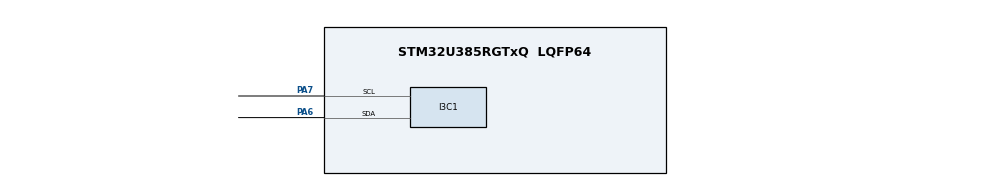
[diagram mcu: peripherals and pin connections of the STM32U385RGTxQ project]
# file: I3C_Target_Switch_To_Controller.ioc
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CORTEX_M33_NS.userName=CORTEX_M33
I3C1.CtrlCapability=ENABLE
I3C1.CtrlRoleRequest=ENABLE
I3C1.IBIPayloadSize=HAL_I3C_PAYLOAD_EMPTY
I3C1.Identifier=0xC6
I3C1.MIPIIdentifier=DEVICE_ID
I3C1.MaxReadDataSize=0xFF
I3C1.MaxWriteDataSize=0xFF
I3C1.Register1=0x0000005e
I3C1.hexBusAvailableDuration=0x5e
Mcu.Family=STM32U3
Mcu.Name=STM32U385RGTxQ
Mcu.Package=LQFP64
Mcu.UserConstants=DEVICE_ID,0x01
NVIC.I3C1_ER_IRQn=true\:0\:0\:false\:false\:true\:true\:true\:true
NVIC.I3C1_EV_IRQn=true\:0\:0\:false\:false\:true\:true\:true\:true
NVIC.PriorityGroup=NVIC_PRIORITYGROUP_4
PA6.Mode=Target
PA6.Signal=I3C1_SDA
PA7.Mode=Target
PA7.Signal=I3C1_SCL
ProjectManager.HeapSize=0x200
ProjectManager.StackSize=0x400
ProjectManager.TargetToolchain=EWARM V9.20
RCC.ADCFreq_Value=96000000
RCC.AHBFreq_Value=96000000
RCC.APB1Freq_Value=96000000
RCC.APB1TimFreq_Value=96000000
RCC.APB2Freq_Value=96000000
RCC.APB2TimFreq_Value=96000000
RCC.APB3Freq_Value=96000000
RCC.CortexFreq_Value=12000000
RCC.HCLKFreq_Value=96000000
RCC.HSE_VALUE=16000000
RCC.HSI48_VALUE=48000000
RCC.HSI_VALUE=16000000
RCC.LSE_VALUE=32768
RCC.LSIDIV_VALUE=32000
RCC.MSISDIV=RCC_MSI_DIV1
RCC.SYSCLKFreq_VALUE=96000000
RCC.USBFreq_Value=96000000
VP_ICACHE_VS_ICACHE.Mode=DirectMappedCache
VP_PWR_VS_DBSignals.Mode=DisableDeadBatterySignals
VP_PWR_VS_LPOM.Mode=PowerOptimisation
VP_PWR_VS_SECSignals.Mode=Security/Privilege
board=custom

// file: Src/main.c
/* USER CODE BEGIN Header */
/**
  ******************************************************************************
  * @file    I3C/I3C_Target_Switch_To_Controller/Src/main.c
  * @author  MCD Application Team
  * @brief   This sample code shows how to use STM32U3xx I3C HAL API to
  *          launch a Controller Roler procedure to a Controller with a communication
  *          process based on Interrupt transfer.
  ******************************************************************************
  * @attention
  *
  * Copyright (c) 2024 STMicroelectronics.
  * All rights reserved.
  *
  * This software is licensed under terms that can be found in the LICENSE file
  * in the root directory of this software component.
  * If no LICENSE file comes with this software, it is provided AS-IS.
  *
  ******************************************************************************
  */
/* USER CODE END Header */
#include "main.h"

/* USER CODE BEGIN PD */
#define I3C_SECONDARY_CONTROLLER_FREQUENCY    2000000  /* I3C Push-Pull Bus frequency: 2 MHz,
                                                          Open Drain is auto-calculated */
/* USER CODE END PD */

I3C_HandleTypeDef hi3c1;

/* USER CODE BEGIN PV */
/* Context buffer related to Frame context, contain different buffer value for a communication */
I3C_XferTypeDef aContextBuffers[2];

/* Variable to catch Controller Role Request event completion */
__IO uint32_t uwCRCompleted = 0;

/* Buffer used for reception during Get CCC procedure */
uint8_t aRxBuffer[0x1F];

/* Buffer used by HAL to compute control data for the Direct Communication */
uint32_t aControlBuffer[0xFF];

/* Descriptor for direct read CCC */
I3C_CCCTypeDef aGET_CCCList[] =
{
    /*   Target Addr              CCC Value    CCC data + defbyte pointer  CCC size + defbyte         Direction       */
    {0x40,          Direct_GETMRL,        {NULL,                  1},              LL_I3C_DIRECTION_READ},
};
/* USER CODE END PV */

void SystemClock_Config(void);
static void MX_GPIO_Init(void);
static void MX_I3C1_Init(void);
static void MX_ICACHE_Init(void);

int main(void)
{

  /* USER CODE BEGIN 1 */
  /* STM32U3xx HAL library initialization:
       - Configure the Flash prefetch
       - Configure the Systick to generate an interrupt each 1 msec
       - Set NVIC Group Priority to 3
       - Low Level Initialization
     */
  /* USER CODE END 1 */

  /* MCU Configuration--------------------------------------------------------*/

  /* Reset of all peripherals, Initializes the Flash interface and the Systick. */
  HAL_Init();

  /* Configure the system clock */
  SystemClock_Config();

  /* Initialize all configured peripherals */
  MX_GPIO_Init();
  MX_I3C1_Init();
  MX_ICACHE_Init();
  /* USER CODE BEGIN 2 */
  /* Configure LD2 */
  BSP_LED_Init(LD2);

  /* Configure User push-button */
  BSP_PB_Init(BUTTON_USER,BUTTON_MODE_GPIO);

  /* Wait for User push-button press before starting the Communication */
  while (BSP_PB_GetState(BUTTON_USER) != GPIO_PIN_RESET)
  {
  }

  /* Wait for User push-button release before starting the Communication */
  while (BSP_PB_GetState(BUTTON_USER) != GPIO_PIN_SET)
  {
  }

  /*##- Prepare Frame send after  Controller Role request ##########################*/
  /* Set used internal buffers information for direct read CCC send after Controller role request */
  aContextBuffers[0].CtrlBuf.pBuffer  = aControlBuffer;
  aContextBuffers[0].CtrlBuf.Size     = 2U ;
  aContextBuffers[0].RxBuf.pBuffer    = aRxBuffer;
  aContextBuffers[0].RxBuf.Size       = 3U;
  aContextBuffers[0].TxBuf.pBuffer    = NULL;
  aContextBuffers[0].TxBuf.Size       = 0U;

  /* Build Frame context */
  if (HAL_I3C_AddDescToFrame(&hi3c1, aGET_CCCList, NULL, &aContextBuffers[0], COUNTOF(aGET_CCCList), I3C_DIRECT_WITHOUT_DEFBYTE_RESTART) != HAL_OK)
  {
    /* Error_Handler() function is called when error occurs. */
    Error_Handler();
  }

  /*##- Send Controller Role request ###############################################*/
  if(HAL_I3C_Tgt_ControlRoleReq_IT(&hi3c1) != HAL_OK)
  {
    /* Error_Handler() function is called when error occurs. */
    Error_Handler();
  }

  /*##- Wait Controller Role Request Acknowledge ##################################*/
  while(uwCRCompleted == 0U)
  {
  }

  /* Transmit direct read (GETMRL) CCC processus to confirm to main controller
     that secondary controller well take control of the bus */
  if (HAL_I3C_Ctrl_ReceiveCCC_IT(&hi3c1, &aContextBuffers[0]) != HAL_OK)
  {
    /* Error_Handler() function is called when error occurs. */
    Error_Handler();
  }

  /*##- Wait for the end of the transfer #################################*/
  /*  Before starting a new communication transfer, you need to check the current
  state of the peripheral; if it's busy you need to wait for the end of current
  transfer before starting a new one.
  For simplicity reasons, this example is just waiting till the end of the
  transfer, but application may perform other tasks while transfer operation
  is ongoing. */
  while (HAL_I3C_GetState(&hi3c1) != HAL_I3C_STATE_READY)
  {
  }
  /* USER CODE END 2 */

  /* Infinite loop */
  while (1)
  {

  }
}

void SystemClock_Config(void)
{
  RCC_OscInitTypeDef RCC_OscInitStruct = {0};
  RCC_ClkInitTypeDef RCC_ClkInitStruct = {0};

  /** Enable Epod Booster
  */
  if (HAL_RCCEx_EpodBoosterClkConfig(RCC_EPODBOOSTER_SOURCE_MSIS, RCC_EPODBOOSTER_DIV1) != HAL_OK)
  {
    Error_Handler();
  }

  if (HAL_PWREx_EnableEpodBooster() != HAL_OK)
  {
    Error_Handler();
  }

  /** Configure the main internal regulator output voltage
  */
  if (HAL_PWREx_ControlVoltageScaling(PWR_REGULATOR_VOLTAGE_SCALE1) != HAL_OK)
  {
    Error_Handler();
  }

  /** Set Flash latency before increasing MSIS
  */
  __HAL_FLASH_SET_LATENCY(FLASH_LATENCY_2);

  /** Initializes the CPU, AHB and APB buses clocks
  */
  RCC_OscInitStruct.OscillatorType = RCC_OSCILLATORTYPE_MSIS;
  RCC_OscInitStruct.MSISState = RCC_MSI_ON;
  RCC_OscInitStruct.MSISSource = RCC_MSI_RC0;
  RCC_OscInitStruct.MSISDiv = RCC_MSI_DIV1;
  if (HAL_RCC_OscConfig(&RCC_OscInitStruct) != HAL_OK)
  {
    Error_Handler();
  }

  /** Initializes the CPU, AHB and APB buses clocks
  */
  RCC_ClkInitStruct.ClockType = RCC_CLOCKTYPE_HCLK|RCC_CLOCKTYPE_SYSCLK
                              |RCC_CLOCKTYPE_PCLK1|RCC_CLOCKTYPE_PCLK2
                              |RCC_CLOCKTYPE_PCLK3;
  RCC_ClkInitStruct.SYSCLKSource = RCC_SYSCLKSOURCE_MSIS;
  RCC_ClkInitStruct.AHBCLKDivider = RCC_SYSCLK_DIV1;
  RCC_ClkInitStruct.APB1CLKDivider = RCC_HCLK_DIV1;
  RCC_ClkInitStruct.APB2CLKDivider = RCC_HCLK_DIV1;
  RCC_ClkInitStruct.APB3CLKDivider = RCC_HCLK_DIV1;

  if (HAL_RCC_ClockConfig(&RCC_ClkInitStruct, FLASH_LATENCY_2) != HAL_OK)
  {
    Error_Handler();
  }
}

static void MX_I3C1_Init(void)
{

  I3C_FifoConfTypeDef sFifoConfig = {0};
  I3C_TgtConfTypeDef sTgtConfig = {0};

  hi3c1.Instance = I3C1;
  hi3c1.Mode = HAL_I3C_MODE_TARGET;
  hi3c1.Init.TgtBusCharacteristic.BusAvailableDuration = 0x5e;
  if (HAL_I3C_Init(&hi3c1) != HAL_OK)
  {
    Error_Handler();
  }

  /** Configure FIFO
  */
  sFifoConfig.RxFifoThreshold = HAL_I3C_RXFIFO_THRESHOLD_1_4;
  sFifoConfig.TxFifoThreshold = HAL_I3C_TXFIFO_THRESHOLD_1_4;
  sFifoConfig.ControlFifo = HAL_I3C_CONTROLFIFO_DISABLE;
  sFifoConfig.StatusFifo = HAL_I3C_STATUSFIFO_DISABLE;

  if (HAL_I3C_SetConfigFifo(&hi3c1, &sFifoConfig) != HAL_OK)
  {
    Error_Handler();
  }

  /** Configure Target
  */
  sTgtConfig.Identifier = 0xC6;
  sTgtConfig.MIPIIdentifier = DEVICE_ID;
  sTgtConfig.CtrlRoleRequest = ENABLE;
  sTgtConfig.HotJoinRequest = DISABLE;
  sTgtConfig.IBIRequest = DISABLE;
  sTgtConfig.IBIPayload = DISABLE;
  sTgtConfig.IBIPayloadSize = HAL_I3C_PAYLOAD_EMPTY;
  sTgtConfig.MaxReadDataSize = 0xFF;
  sTgtConfig.MaxWriteDataSize = 0xFF;
  sTgtConfig.CtrlCapability = ENABLE;
  sTgtConfig.GroupAddrCapability = DISABLE;
  sTgtConfig.DataTurnAroundDuration = HAL_I3C_TURNAROUND_TIME_TSCO_LESS_12NS;
  sTgtConfig.MaxReadTurnAround = 0;
  sTgtConfig.MaxDataSpeed = HAL_I3C_GETMXDS_FORMAT_1;
  sTgtConfig.MaxSpeedLimitation = DISABLE;
  sTgtConfig.HandOffActivityState = HAL_I3C_HANDOFF_ACTIVITY_STATE_0;
  sTgtConfig.HandOffDelay = DISABLE;
  sTgtConfig.PendingReadMDB = DISABLE;
  if (HAL_I3C_Tgt_Config(&hi3c1, &sTgtConfig) != HAL_OK)
  {
    Error_Handler();
  }

}

static void MX_ICACHE_Init(void)
{

  /** Enable instruction cache in 1-way (direct mapped cache)
  */
  if (HAL_ICACHE_ConfigAssociativityMode(ICACHE_1WAY) != HAL_OK)
  {
    Error_Handler();
  }
  if (HAL_ICACHE_Enable() != HAL_OK)
  {
    Error_Handler();
  }

}

static void MX_GPIO_Init(void)
{

  /* GPIO Ports Clock Enable */
  __HAL_RCC_GPIOA_CLK_ENABLE();

}

/* USER CODE BEGIN 4 */
/**
  * @brief I3C notify callback after receiving a notification.
  *        The main objective of this user function is to check on the notification ID and assign 1 to the global
  *        variable used to indicate that the event is well finished.
  * @par Called functions
  * - HAL_I3C_NotifyCallback()
  * @retval None
  */
void HAL_I3C_NotifyCallback(I3C_HandleTypeDef *hi3c, uint32_t eventId)
{
  LL_I3C_CtrlBusConfTypeDef CtrlBusConf;
  I3C_CtrlTimingTypeDef CtrlTiming;

  if ((eventId & EVENT_ID_GETACCCR) == EVENT_ID_GETACCCR)
  {
    /* Switch mode to Controller */
    hi3c1.Mode = HAL_I3C_MODE_CONTROLLER;

    /* Fill the required parameters to calculate the Controller Bus Timing */
    CtrlTiming.clockSrcFreq = HAL_RCCEx_GetPeriphCLKFreq(RCC_PERIPHCLK_I3C1);
    CtrlTiming.i3cPPFreq = I3C_SECONDARY_CONTROLLER_FREQUENCY;
    CtrlTiming.i2cODFreq = 0;
    CtrlTiming.dutyCycle = 50;
    CtrlTiming.busType = I3C_PURE_I3C_BUS;

    /* Calculate the new timing for Controller */
    I3C_CtrlTimingComputation(&CtrlTiming, &CtrlBusConf);

    /* Update Controller Bus characteristic */
    HAL_I3C_Ctrl_BusCharacteristicConfig(hi3c, &CtrlBusConf);

    /* Toggle global variable to inform main application of the completion of the controller role request */
    uwCRCompleted = 1;
  }
}

/**
  * @brief  Controller Reception Complete callback.
  * @param  hi3c : [IN] Pointer to an I3C_HandleTypeDef structure that contains the configuration information
  *                     for the specified I3C.
  * @retval None
  */
void HAL_I3C_CtrlRxCpltCallback(I3C_HandleTypeDef *hi3c)
{
  /* Toggle LD2: Transfer in Reception process is correct */
  BSP_LED_Toggle(LD2);
}

/* USER CODE END 4 */

void Error_Handler(void)
{
  /* USER CODE BEGIN Error_Handler_Debug */
  /* Error if LD2 is slowly blinking (1 sec. period) */
  while (1)
  {
    BSP_LED_Toggle(LD2);
    HAL_Delay(1000);
  }
  /* USER CODE END Error_Handler_Debug */
}

#ifdef  USE_FULL_ASSERT
/**
  * @brief  Reports the name of the source file and the source line number
  *         where the assert_param error has occurred.
  * @param  file: pointer to the source file name
  * @param  line: assert_param error line source number
  * @retval None
  */
void assert_failed(uint8_t *file, uint32_t line)
{
  /* USER CODE BEGIN 6 */
  /* User can add his own implementation to report the file name and line number,
     ex: printf("Wrong parameters value: file %s on line %d\r\n", file, line) */
  /* Infinite Loop */
  while(1)
  {
  }
  /* USER CODE END 6 */
}
#endif /* USE_FULL_ASSERT */
